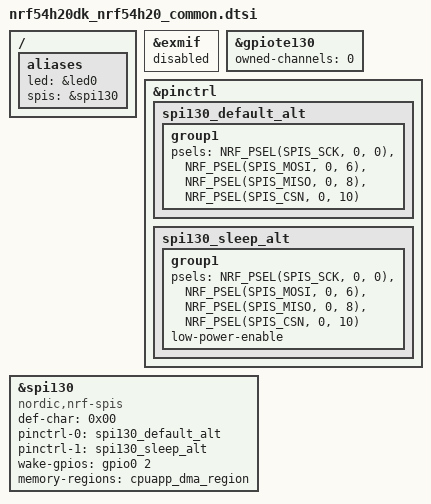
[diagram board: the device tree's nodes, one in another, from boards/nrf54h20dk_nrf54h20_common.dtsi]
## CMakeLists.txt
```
#
# Copyright (c) 2025 Nordic Semiconductor ASA
# SPDX-License-Identifier: Apache-2.0
#

cmake_minimum_required(VERSION 3.28.0)

find_package(Zephyr REQUIRED HINTS $ENV{ZEPHYR_BASE})

if(NOT SYSBUILD)
  message(FATAL_ERROR "This is a multi-image application that should be built using sysbuild.\n"
    "Add --sysbuild argument to west build command to prepare all the images.")
endif()

project(spis_wakeup)

target_sources(app PRIVATE src/main.c)
```

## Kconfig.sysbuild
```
# Copyright (c) 2025 Nordic Semiconductor ASA
# SPDX-License-Identifier: Apache-2.0

source "$(ZEPHYR_BASE)/share/sysbuild/Kconfig"

choice REMOTE_NRF54H20_CORE
	prompt "Remote nRF54h20 core"
	default REMOTE_NRF54H20_CPURAD_CORE
	depends on SOC_NRF54H20_CPUAPP

config REMOTE_NRF54H20_CPUPPR_CORE
	bool "ppr core"

config REMOTE_NRF54H20_CPURAD_CORE
	bool "cpurad"

endchoice

config REMOTE_BOARD
	string
	default "$(BOARD)/nrf54h20/cpurad" if SOC_NRF54H20_CPUAPP && REMOTE_NRF54H20_CPURAD_CORE
	default "$(BOARD)/nrf54h20/cpuppr/xip" if SOC_NRF54H20_CPUAPP && REMOTE_NRF54H20_CPUPPR_CORE
```

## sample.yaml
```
common:
  sysbuild: true
  depends_on: spi
  tags:
    - spi
  harness: console
  harness_config:
    fixture: spi_loopback
    type: multi_line
    ordered: true
    regex:
      - ".*SPIS: waiting for SPI transfer"
      - ".*SPIS: woken up by"

sample:
  name: SPI wakeup sample
tests:
  sample.drivers.spis.wakeup:
    platform_allow:
      - nrf54h20dk/nrf54h20/cpuapp
    integration_platforms:
      - nrf54h20dk/nrf54h20/cpuapp
    extra_args:
      - SB_CONFIG_REMOTE_NRF54H20_CPURAD_CORE=y
      - spis_wakeup_SNIPPET=nordic-rad
  sample.drivers.spis.wakeup.ppr:
    platform_allow:
      - nrf54h20dk/nrf54h20/cpuapp
    integration_platforms:
      - nrf54h20dk/nrf54h20/cpuapp
    extra_args:
      - SB_CONFIG_REMOTE_NRF54H20_CPUPPR_CORE=y
      - spis_wakeup_SNIPPET=nordic-ppr-xip
```

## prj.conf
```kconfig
CONFIG_SPI=y
CONFIG_SPI_PERIPHERAL=y
CONFIG_GPIO=y

CONFIG_PM=y
CONFIG_PM_DEVICE=y
CONFIG_PM_DEVICE_RUNTIME=y

CONFIG_ASSERT=y

CONFIG_LOG=y
```

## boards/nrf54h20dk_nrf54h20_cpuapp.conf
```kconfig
# Copyright (c) 2025 Nordic Semiconductor ASA
# SPDX-License-Identifier: Apache-2.0

CONFIG_SOC_NRF54H20_CPURAD_ENABLE=y
```

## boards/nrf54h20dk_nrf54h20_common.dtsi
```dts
/*
 * Copyright (c) 2025 Nordic Semiconductor ASA
 * SPDX-License-Identifier: Apache-2.0
 */

/ {
	aliases {
		led = &led0;
		spis = &spi130;
		/delete-property/ sw0;
		/delete-property/ sw1;
		/delete-property/ sw2;
		/delete-property/ sw3;
		/delete-property/ mcuboot-led0;
		/delete-property/ mcuboot-button0;
	};
	/delete-node/ buttons;
};

&exmif {
	status = "disabled";
};

&gpiote130 {
	owned-channels = <0>;
	status = "okay";
};

&pinctrl {
	spi130_default_alt: spi130_default_alt {
		group1 {
			psels = <NRF_PSEL(SPIS_SCK, 0, 0)>,
				<NRF_PSEL(SPIS_MOSI, 0, 6)>,
				<NRF_PSEL(SPIS_MISO, 0, 8)>,
				<NRF_PSEL(SPIS_CSN, 0, 10)>;
		};
	};

	spi130_sleep_alt: spi130_sleep_alt {
		group1 {
			psels = <NRF_PSEL(SPIS_SCK, 0, 0)>,
				<NRF_PSEL(SPIS_MOSI, 0, 6)>,
				<NRF_PSEL(SPIS_MISO, 0, 8)>,
				<NRF_PSEL(SPIS_CSN, 0, 10)>;
			low-power-enable;
		};
	};
};

&spi130 {
	compatible = "nordic,nrf-spis";
	def-char = <0x00>;
	pinctrl-0 = <&spi130_default_alt>;
	pinctrl-1 = <&spi130_sleep_alt>;
	pinctrl-names = "default", "sleep";
	wake-gpios = <&gpio0 2 GPIO_ACTIVE_HIGH>;
	memory-regions = <&cpuapp_dma_region>;
	status = "okay";
	/delete-property/ rx-delay-supported;
	/delete-property/ rx-delay;
};
```

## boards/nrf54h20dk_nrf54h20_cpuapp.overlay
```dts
/*
 * Copyright (c) 2025 Nordic Semiconductor ASA
 * SPDX-License-Identifier: Apache-2.0
 */

#include "nrf54h20dk_nrf54h20_common.dtsi"

/* LED1 will be used by the cpurad core. */
/ {
	aliases {
		/delete-property/ led1;
	};
};

/delete-node/ &led1;
```

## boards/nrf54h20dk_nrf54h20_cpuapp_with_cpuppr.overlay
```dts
/*
 * Copyright (c) 2025 Nordic Semiconductor ASA
 * SPDX-License-Identifier: Apache-2.0
 */

#include "nrf54h20dk_nrf54h20_common.dtsi"

&spi131 {
	interrupt-parent = <&cpuppr_clic>;
	status = "reserved";
};

&uart135 {
	interrupt-parent = <&cpuppr_clic>;
	status = "reserved";
};
```

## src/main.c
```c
/*
 * Copyright (c) 2025 Nordic Semiconductor ASA
 * SPDX-License-Identifier: Apache-2.0
 */

#include <zephyr/kernel.h>
#include <zephyr/logging/log.h>
#include <zephyr/drivers/spi.h>
#include <zephyr/drivers/gpio.h>

#define BUF_SIZE 32
static const struct device *spis_dev = DEVICE_DT_GET(DT_ALIAS(spis));
static const struct spi_config spis_config = {
	.operation = SPI_OP_MODE_PERIPHERAL | SPI_WORD_SET(8)};

static const struct gpio_dt_spec led = GPIO_DT_SPEC_GET(DT_ALIAS(led), gpios);

LOG_MODULE_REGISTER(spi_wakeup);

int main(void)
{
	bool status;
	static char rx_buffer[BUF_SIZE];
	struct spi_buf rx_spi_bufs = {.buf = rx_buffer, .len = sizeof(rx_buffer)};
	struct spi_buf_set rx_spi_buf_set = {.buffers = &rx_spi_bufs, .count = 1};

	LOG_INF("Hello world from %s", CONFIG_BOARD_TARGET);

	status = gpio_is_ready_dt(&led);
	__ASSERT(status, "Error: GPIO Device not ready");

	status = gpio_pin_configure_dt(&led, GPIO_OUTPUT_ACTIVE);
	__ASSERT(status == 0, "Could not configure led GPIO");

	status = device_is_ready(spis_dev);
	__ASSERT(status, "Error: SPI device is not ready");

	while (1) {
		memset(rx_buffer, 0x00, sizeof(rx_buffer));
		LOG_INF("SPIS: waiting for SPI transfer; going to sleep...");
		gpio_pin_set_dt(&led, 0);
		spi_read(spis_dev, &spis_config, &rx_spi_buf_set);
		gpio_pin_set_dt(&led, 1);
		LOG_INF("SPIS: woken up by %s", rx_buffer);
		LOG_INF("SPIS: will be active for 500ms after transfer");
		k_busy_wait(500000);
	}

	return 0;
}
```
